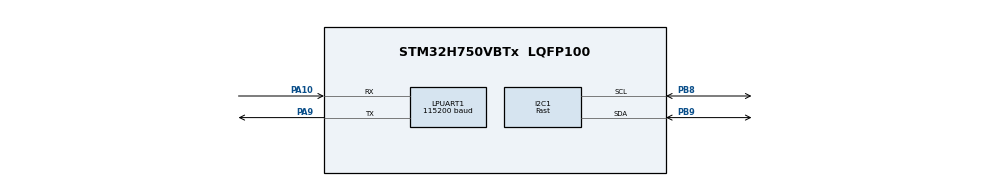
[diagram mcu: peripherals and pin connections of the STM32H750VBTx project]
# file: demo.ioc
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Dma.I2C1_RX.1.Direction=DMA_PERIPH_TO_MEMORY
Dma.I2C1_RX.1.EventEnable=DISABLE
Dma.I2C1_RX.1.FIFOMode=DMA_FIFOMODE_DISABLE
Dma.I2C1_RX.1.Instance=DMA1_Stream1
Dma.I2C1_RX.1.MemDataAlignment=DMA_MDATAALIGN_BYTE
Dma.I2C1_RX.1.MemInc=DMA_MINC_ENABLE
Dma.I2C1_RX.1.Mode=DMA_NORMAL
Dma.I2C1_RX.1.PeriphDataAlignment=DMA_PDATAALIGN_BYTE
Dma.I2C1_RX.1.PeriphInc=DMA_PINC_DISABLE
Dma.I2C1_RX.1.Polarity=HAL_DMAMUX_REQ_GEN_RISING
Dma.I2C1_RX.1.Priority=DMA_PRIORITY_LOW
Dma.I2C1_RX.1.RequestNumber=1
Dma.I2C1_RX.1.SignalID=NONE
Dma.I2C1_RX.1.SyncEnable=DISABLE
Dma.I2C1_RX.1.SyncPolarity=HAL_DMAMUX_SYNC_NO_EVENT
Dma.I2C1_RX.1.SyncRequestNumber=1
Dma.I2C1_RX.1.SyncSignalID=NONE
Dma.I2C1_TX.0.Direction=DMA_MEMORY_TO_PERIPH
Dma.I2C1_TX.0.EventEnable=DISABLE
Dma.I2C1_TX.0.FIFOMode=DMA_FIFOMODE_DISABLE
Dma.I2C1_TX.0.Instance=DMA1_Stream0
Dma.I2C1_TX.0.MemDataAlignment=DMA_MDATAALIGN_BYTE
Dma.I2C1_TX.0.MemInc=DMA_MINC_ENABLE
Dma.I2C1_TX.0.Mode=DMA_NORMAL
Dma.I2C1_TX.0.PeriphDataAlignment=DMA_PDATAALIGN_BYTE
Dma.I2C1_TX.0.PeriphInc=DMA_PINC_DISABLE
Dma.I2C1_TX.0.Polarity=HAL_DMAMUX_REQ_GEN_RISING
Dma.I2C1_TX.0.Priority=DMA_PRIORITY_LOW
Dma.I2C1_TX.0.RequestNumber=1
Dma.I2C1_TX.0.SignalID=NONE
Dma.I2C1_TX.0.SyncEnable=DISABLE
Dma.I2C1_TX.0.SyncPolarity=HAL_DMAMUX_SYNC_NO_EVENT
Dma.I2C1_TX.0.SyncRequestNumber=1
Dma.I2C1_TX.0.SyncSignalID=NONE
Dma.Request0=I2C1_TX
Dma.Request1=I2C1_RX
I2C1.I2C_Fall_Time=0
I2C1.I2C_Rise_Time=0
I2C1.I2C_Speed_Mode=I2C_Fast
I2C1.Speed=400
I2C1.Timing=0x00300F38
LPUART1.BaudRate=115200
Mcu.Family=STM32H7
Mcu.Name=STM32H750VBTx
Mcu.Package=LQFP100
NVIC.DMA1_Stream0_IRQn=true\:2\:0\:true\:false\:true\:false\:true\:true
NVIC.DMA1_Stream1_IRQn=true\:0\:0\:false\:false\:true\:false\:true\:true
NVIC.I2C1_ER_IRQn=true\:1\:0\:true\:false\:true\:true\:true\:true
NVIC.I2C1_EV_IRQn=true\:1\:0\:true\:false\:true\:true\:true\:true
NVIC.PriorityGroup=NVIC_PRIORITYGROUP_4
PA10.Mode=Asynchronous
PA10.Signal=LPUART1_RX
PA9.Mode=Asynchronous
PA9.Signal=LPUART1_TX
PB8.Mode=I2C
PB8.Signal=I2C1_SCL
PB9.Mode=I2C
PB9.Signal=I2C1_SDA
PC14-OSC32_IN\ (OSC32_IN).Mode=LSE-External-Oscillator
PC14-OSC32_IN\ (OSC32_IN).Signal=RCC_OSC32_IN
PC15-OSC32_OUT\ (OSC32_OUT).Mode=LSE-External-Oscillator
PC15-OSC32_OUT\ (OSC32_OUT).Signal=RCC_OSC32_OUT
PH0-OSC_IN\ (PH0).Mode=HSE-External-Oscillator
PH0-OSC_IN\ (PH0).Signal=RCC_OSC_IN
PH1-OSC_OUT\ (PH1).Mode=HSE-External-Oscillator
PH1-OSC_OUT\ (PH1).Signal=RCC_OSC_OUT
ProjectManager.HeapSize=0x200
ProjectManager.StackSize=0x400
ProjectManager.TargetToolchain=MDK-ARM V5.32
RCC.ADCFreq_Value=129000000
RCC.APB1Freq_Value=32000000
RCC.APB2Freq_Value=32000000
RCC.APB3Freq_Value=32000000
RCC.APB4Freq_Value=32000000
RCC.CortexFreq_Value=64000000
RCC.D1PPRE=RCC_APB3_DIV2
RCC.D2PPRE1=RCC_APB1_DIV2
RCC.D2PPRE2=RCC_APB2_DIV2
RCC.D3PPRE=RCC_APB4_DIV2
RCC.HCLKFreq_Value=64000000
RCC.SYSCLKFreq_VALUE=64000000
RCC.USBFreq_Value=129000000
board=custom

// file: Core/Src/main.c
/* USER CODE BEGIN Header */
/**
  ******************************************************************************
  * @file           : main.c
  * @brief          : Main program body
  ******************************************************************************
  * @attention
  *
  * Copyright (c) 2023 STMicroelectronics.
  * All rights reserved.
  *
  * This software is licensed under terms that can be found in the LICENSE file
  * in the root directory of this software component.
  * If no LICENSE file comes with this software, it is provided AS-IS.
  *
  ******************************************************************************
  */
/* USER CODE END Header */
#include "main.h"
#include "dma.h"
#include "i2c.h"
#include "usart.h"
#include "gpio.h"

/* USER CODE BEGIN Includes */
#include "24C02Dev.h"
/* USER CODE END Includes */

void SystemClock_Config(void);

int main(void)
{

  /* MCU Configuration--------------------------------------------------------*/

  /* Reset of all peripherals, Initializes the Flash interface and the Systick. */
  HAL_Init();

  /* Configure the system clock */
  SystemClock_Config();

  /* Initialize all configured peripherals */
  MX_GPIO_Init();
  MX_LPUART1_UART_Init();
  MX_DMA_Init();
  MX_I2C1_Init();
  /* USER CODE BEGIN 2 */
  AT24C02_Inspect();
  /* USER CODE END 2 */

  /* Infinite loop */
  while (1)
  {

  }
}

void SystemClock_Config(void)
{
  RCC_OscInitTypeDef RCC_OscInitStruct = {0};
  RCC_ClkInitTypeDef RCC_ClkInitStruct = {0};

  /** Supply configuration update enable
  */
  HAL_PWREx_ConfigSupply(PWR_LDO_SUPPLY);

  /** Configure the main internal regulator output voltage
  */
  __HAL_PWR_VOLTAGESCALING_CONFIG(PWR_REGULATOR_VOLTAGE_SCALE3);

  while(!__HAL_PWR_GET_FLAG(PWR_FLAG_VOSRDY)) {}

  /** Initializes the RCC Oscillators according to the specified parameters
  * in the RCC_OscInitTypeDef structure.
  */
  RCC_OscInitStruct.OscillatorType = RCC_OSCILLATORTYPE_HSI;
  RCC_OscInitStruct.HSIState = RCC_HSI_DIV1;
  RCC_OscInitStruct.HSICalibrationValue = RCC_HSICALIBRATION_DEFAULT;
  RCC_OscInitStruct.PLL.PLLState = RCC_PLL_NONE;
  if (HAL_RCC_OscConfig(&RCC_OscInitStruct) != HAL_OK)
  {
    Error_Handler();
  }

  /** Initializes the CPU, AHB and APB buses clocks
  */
  RCC_ClkInitStruct.ClockType = RCC_CLOCKTYPE_HCLK|RCC_CLOCKTYPE_SYSCLK
                              |RCC_CLOCKTYPE_PCLK1|RCC_CLOCKTYPE_PCLK2
                              |RCC_CLOCKTYPE_D3PCLK1|RCC_CLOCKTYPE_D1PCLK1;
  RCC_ClkInitStruct.SYSCLKSource = RCC_SYSCLKSOURCE_HSI;
  RCC_ClkInitStruct.SYSCLKDivider = RCC_SYSCLK_DIV1;
  RCC_ClkInitStruct.AHBCLKDivider = RCC_HCLK_DIV1;
  RCC_ClkInitStruct.APB3CLKDivider = RCC_APB3_DIV2;
  RCC_ClkInitStruct.APB1CLKDivider = RCC_APB1_DIV2;
  RCC_ClkInitStruct.APB2CLKDivider = RCC_APB2_DIV2;
  RCC_ClkInitStruct.APB4CLKDivider = RCC_APB4_DIV2;

  if (HAL_RCC_ClockConfig(&RCC_ClkInitStruct, FLASH_LATENCY_1) != HAL_OK)
  {
    Error_Handler();
  }
}

void Error_Handler(void)
{
  __disable_irq();
  while (1)
  {
  }
}
